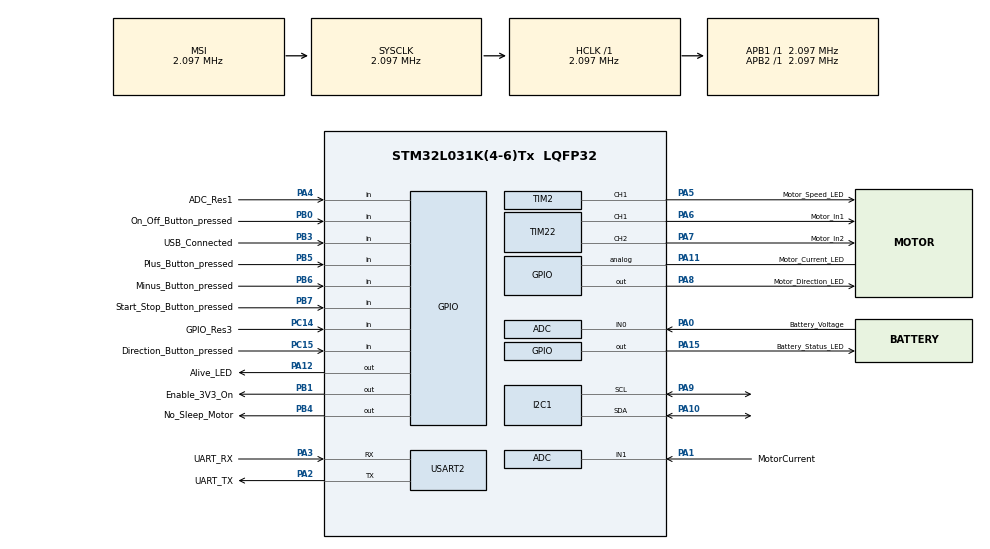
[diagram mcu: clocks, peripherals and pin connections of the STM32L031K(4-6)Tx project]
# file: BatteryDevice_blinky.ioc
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I2C1.Timing=0x00000608
Mcu.Family=STM32L0
Mcu.Name=STM32L031K(4-6)Tx
Mcu.Package=LQFP32
PA0-CK_IN.GPIO_Label=Battery_Voltage
PA0-CK_IN.Mode=IN0
PA0-CK_IN.Signal=ADC_IN0
PA1.GPIO_Label=MotorCurrent
PA1.Mode=IN1
PA1.Signal=ADC_IN1
PA10.Mode=I2C
PA10.Signal=I2C1_SDA
PA11.GPIO_Label=Motor_Current_LED
PA11.Signal=GPIO_Analog
PA12.GPIO_Label=Alive_LED
PA12.Signal=GPIO_Output
PA13.Mode=Serial_Wire
PA13.Signal=SYS_SWDIO
PA14.Mode=Serial_Wire
PA14.Signal=SYS_SWCLK
PA15.GPIO_Label=Battery_Status_LED
PA15.Signal=GPIO_Output
PA2.GPIO_Label=UART_TX
PA2.Mode=Asynchronous
PA2.Signal=USART2_TX
PA3.GPIO_Label=UART_RX
PA3.Mode=Asynchronous
PA3.Signal=USART2_RX
PA4.GPIO_Label=ADC_Res1
PA4.Signal=GPIO_Input
PA5.GPIO_Label=Motor_Speed_LED
PA5.Signal=S_TIM2_CH1
PA6.GPIO_Label=Motor_In1
PA6.Signal=S_TIM22_CH1
PA7.GPIO_Label=Motor_In2
PA7.Signal=S_TIM22_CH2
PA8.GPIO_Label=Motor_Direction_LED
PA8.Signal=GPIO_Output
PA9.Mode=I2C
PA9.Signal=I2C1_SCL
PB0.GPIO_Label=On_Off_Button_pressed
PB0.Signal=GPIO_Input
PB1.GPIO_Label=Enable_3V3_On
PB1.Signal=GPIO_Output
PB3.GPIO_Label=USB_Connected
PB3.Signal=GPIO_Input
PB4.GPIO_Label=No_Sleep_Motor
PB4.Signal=GPIO_Output
PB5.GPIO_Label=Plus_Button_pressed
PB5.Signal=GPIO_Input
PB6.GPIO_Label=Minus_Button_pressed
PB6.Signal=GPIO_Input
PB7.GPIO_Label=Start_Stop_Button_pressed
PB7.Signal=GPIO_Input
PC14-OSC32_IN.GPIO_Label=GPIO_Res3
PC14-OSC32_IN.Signal=GPIO_Input
PC15-OSC32_OUT.GPIO_Label=Direction_Button_pressed
PC15-OSC32_OUT.Signal=GPIO_Input
ProjectManager.HeapSize=0x200
ProjectManager.StackSize=0x400
ProjectManager.TargetToolchain=STM32CubeIDE
RCC.AHBFreq_Value=2097000
RCC.APB1Freq_Value=2097000
RCC.APB1TimFreq_Value=2097000
RCC.APB2Freq_Value=2097000
RCC.APB2TimFreq_Value=2097000
RCC.HSE_VALUE=8000000
RCC.HSI16_VALUE=16000000
RCC.HSI_VALUE=16000000
RCC.LSE_VALUE=32768
RCC.MSI_VALUE=2097000
RCC.SYSCLKFreq_VALUE=2097000
RCC.VCOOutputFreq_Value=48000000
SH.S_TIM22_CH1.0=TIM22_CH1,PWM Generation1 CH1
SH.S_TIM22_CH2.0=TIM22_CH2,PWM Generation2 CH2
SH.S_TIM2_CH1.0=TIM2_CH1,PWM Generation1 CH1
TIM2.Channel-PWM\ Generation1\ CH1=TIM_CHANNEL_1
TIM2.Period=100
TIM2.Prescaler=16000-1
TIM22.Channel-PWM\ Generation1\ CH1=TIM_CHANNEL_1
TIM22.Channel-PWM\ Generation2\ CH2=TIM_CHANNEL_2
USART2.VirtualMode-Asynchronous=VM_ASYNC
board=custom

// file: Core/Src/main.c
/* USER CODE BEGIN Header */
/**
  ******************************************************************************
  * @file           : main.c
  * @brief          : Main program body
  ******************************************************************************
  * @attention
  *
  * Copyright (c) 2025 STMicroelectronics.
  * All rights reserved.
  *
  * This software is licensed under terms that can be found in the LICENSE file
  * in the root directory of this software component.
  * If no LICENSE file comes with this software, it is provided AS-IS.
  *
  ******************************************************************************
  */
/* USER CODE END Header */
#include "main.h"

ADC_HandleTypeDef hadc;

I2C_HandleTypeDef hi2c1;

TIM_HandleTypeDef htim2;
TIM_HandleTypeDef htim22;

UART_HandleTypeDef huart2;

void SystemClock_Config(void);
static void MX_GPIO_Init(void);
static void MX_ADC_Init(void);
static void MX_I2C1_Init(void);
static void MX_TIM2_Init(void);
static void MX_TIM22_Init(void);
static void MX_USART2_UART_Init(void);

int main(void)
{

  /* MCU Configuration--------------------------------------------------------*/

  /* Reset of all peripherals, Initializes the Flash interface and the Systick. */
  HAL_Init();

  /* Configure the system clock */
  SystemClock_Config();

  /* Initialize all configured peripherals */
  MX_GPIO_Init();
  MX_ADC_Init();
  MX_I2C1_Init();
  MX_TIM2_Init();
  MX_TIM22_Init();
  MX_USART2_UART_Init();

  /* Infinite loop */
  /* USER CODE BEGIN WHILE */
  while (1)
  {
	  HAL_GPIO_TogglePin(Alive_LED_GPIO_Port, Alive_LED_Pin); // LED toggeln
	  HAL_DELAY(300);

	  /* USER CODE END WHILE */

  }
}

void SystemClock_Config(void)
{
  RCC_OscInitTypeDef RCC_OscInitStruct = {0};
  RCC_ClkInitTypeDef RCC_ClkInitStruct = {0};
  RCC_PeriphCLKInitTypeDef PeriphClkInit = {0};

  /** Configure the main internal regulator output voltage
  */
  __HAL_PWR_VOLTAGESCALING_CONFIG(PWR_REGULATOR_VOLTAGE_SCALE1);

  /** Initializes the RCC Oscillators according to the specified parameters
  * in the RCC_OscInitTypeDef structure.
  */
  RCC_OscInitStruct.OscillatorType = RCC_OSCILLATORTYPE_MSI;
  RCC_OscInitStruct.MSIState = RCC_MSI_ON;
  RCC_OscInitStruct.MSICalibrationValue = 0;
  RCC_OscInitStruct.MSIClockRange = RCC_MSIRANGE_5;
  RCC_OscInitStruct.PLL.PLLState = RCC_PLL_NONE;
  if (HAL_RCC_OscConfig(&RCC_OscInitStruct) != HAL_OK)
  {
    Error_Handler();
  }

  /** Initializes the CPU, AHB and APB buses clocks
  */
  RCC_ClkInitStruct.ClockType = RCC_CLOCKTYPE_HCLK|RCC_CLOCKTYPE_SYSCLK
                              |RCC_CLOCKTYPE_PCLK1|RCC_CLOCKTYPE_PCLK2;
  RCC_ClkInitStruct.SYSCLKSource = RCC_SYSCLKSOURCE_MSI;
  RCC_ClkInitStruct.AHBCLKDivider = RCC_SYSCLK_DIV1;
  RCC_ClkInitStruct.APB1CLKDivider = RCC_HCLK_DIV1;
  RCC_ClkInitStruct.APB2CLKDivider = RCC_HCLK_DIV1;

  if (HAL_RCC_ClockConfig(&RCC_ClkInitStruct, FLASH_LATENCY_0) != HAL_OK)
  {
    Error_Handler();
  }
  PeriphClkInit.PeriphClockSelection = RCC_PERIPHCLK_USART2|RCC_PERIPHCLK_I2C1;
  PeriphClkInit.Usart2ClockSelection = RCC_USART2CLKSOURCE_PCLK1;
  PeriphClkInit.I2c1ClockSelection = RCC_I2C1CLKSOURCE_PCLK1;
  if (HAL_RCCEx_PeriphCLKConfig(&PeriphClkInit) != HAL_OK)
  {
    Error_Handler();
  }
}

static void MX_ADC_Init(void)
{

  ADC_ChannelConfTypeDef sConfig = {0};

  /** Configure the global features of the ADC (Clock, Resolution, Data Alignment and number of conversion)
  */
  hadc.Instance = ADC1;
  hadc.Init.OversamplingMode = DISABLE;
  hadc.Init.ClockPrescaler = ADC_CLOCK_SYNC_PCLK_DIV1;
  hadc.Init.Resolution = ADC_RESOLUTION_12B;
  hadc.Init.SamplingTime = ADC_SAMPLETIME_1CYCLE_5;
  hadc.Init.ScanConvMode = ADC_SCAN_DIRECTION_FORWARD;
  hadc.Init.DataAlign = ADC_DATAALIGN_RIGHT;
  hadc.Init.ContinuousConvMode = DISABLE;
  hadc.Init.DiscontinuousConvMode = DISABLE;
  hadc.Init.ExternalTrigConvEdge = ADC_EXTERNALTRIGCONVEDGE_NONE;
  hadc.Init.ExternalTrigConv = ADC_SOFTWARE_START;
  hadc.Init.DMAContinuousRequests = DISABLE;
  hadc.Init.EOCSelection = ADC_EOC_SINGLE_CONV;
  hadc.Init.Overrun = ADC_OVR_DATA_PRESERVED;
  hadc.Init.LowPowerAutoWait = DISABLE;
  hadc.Init.LowPowerFrequencyMode = ENABLE;
  hadc.Init.LowPowerAutoPowerOff = DISABLE;
  if (HAL_ADC_Init(&hadc) != HAL_OK)
  {
    Error_Handler();
  }

  /** Configure for the selected ADC regular channel to be converted.
  */
  sConfig.Channel = ADC_CHANNEL_0;
  sConfig.Rank = ADC_RANK_CHANNEL_NUMBER;
  if (HAL_ADC_ConfigChannel(&hadc, &sConfig) != HAL_OK)
  {
    Error_Handler();
  }

  /** Configure for the selected ADC regular channel to be converted.
  */
  sConfig.Channel = ADC_CHANNEL_1;
  if (HAL_ADC_ConfigChannel(&hadc, &sConfig) != HAL_OK)
  {
    Error_Handler();
  }

}

static void MX_I2C1_Init(void)
{

  hi2c1.Instance = I2C1;
  hi2c1.Init.Timing = 0x00000608;
  hi2c1.Init.OwnAddress1 = 0;
  hi2c1.Init.AddressingMode = I2C_ADDRESSINGMODE_7BIT;
  hi2c1.Init.DualAddressMode = I2C_DUALADDRESS_DISABLE;
  hi2c1.Init.OwnAddress2 = 0;
  hi2c1.Init.OwnAddress2Masks = I2C_OA2_NOMASK;
  hi2c1.Init.GeneralCallMode = I2C_GENERALCALL_DISABLE;
  hi2c1.Init.NoStretchMode = I2C_NOSTRETCH_DISABLE;
  if (HAL_I2C_Init(&hi2c1) != HAL_OK)
  {
    Error_Handler();
  }

  /** Configure Analogue filter
  */
  if (HAL_I2CEx_ConfigAnalogFilter(&hi2c1, I2C_ANALOGFILTER_ENABLE) != HAL_OK)
  {
    Error_Handler();
  }

  /** Configure Digital filter
  */
  if (HAL_I2CEx_ConfigDigitalFilter(&hi2c1, 0) != HAL_OK)
  {
    Error_Handler();
  }

}

static void MX_TIM2_Init(void)
{

  TIM_MasterConfigTypeDef sMasterConfig = {0};
  TIM_OC_InitTypeDef sConfigOC = {0};

  htim2.Instance = TIM2;
  htim2.Init.Prescaler = 16000-1;
  htim2.Init.CounterMode = TIM_COUNTERMODE_UP;
  htim2.Init.Period = 100;
  htim2.Init.ClockDivision = TIM_CLOCKDIVISION_DIV1;
  htim2.Init.AutoReloadPreload = TIM_AUTORELOAD_PRELOAD_DISABLE;
  if (HAL_TIM_PWM_Init(&htim2) != HAL_OK)
  {
    Error_Handler();
  }
  sMasterConfig.MasterOutputTrigger = TIM_TRGO_RESET;
  sMasterConfig.MasterSlaveMode = TIM_MASTERSLAVEMODE_DISABLE;
  if (HAL_TIMEx_MasterConfigSynchronization(&htim2, &sMasterConfig) != HAL_OK)
  {
    Error_Handler();
  }
  sConfigOC.OCMode = TIM_OCMODE_PWM1;
  sConfigOC.Pulse = 0;
  sConfigOC.OCPolarity = TIM_OCPOLARITY_HIGH;
  sConfigOC.OCFastMode = TIM_OCFAST_DISABLE;
  if (HAL_TIM_PWM_ConfigChannel(&htim2, &sConfigOC, TIM_CHANNEL_1) != HAL_OK)
  {
    Error_Handler();
  }
  HAL_TIM_MspPostInit(&htim2);

}

static void MX_TIM22_Init(void)
{

  TIM_MasterConfigTypeDef sMasterConfig = {0};
  TIM_OC_InitTypeDef sConfigOC = {0};

  htim22.Instance = TIM22;
  htim22.Init.Prescaler = 0;
  htim22.Init.CounterMode = TIM_COUNTERMODE_UP;
  htim22.Init.Period = 65535;
  htim22.Init.ClockDivision = TIM_CLOCKDIVISION_DIV1;
  htim22.Init.AutoReloadPreload = TIM_AUTORELOAD_PRELOAD_DISABLE;
  if (HAL_TIM_PWM_Init(&htim22) != HAL_OK)
  {
    Error_Handler();
  }
  sMasterConfig.MasterOutputTrigger = TIM_TRGO_RESET;
  sMasterConfig.MasterSlaveMode = TIM_MASTERSLAVEMODE_DISABLE;
  if (HAL_TIMEx_MasterConfigSynchronization(&htim22, &sMasterConfig) != HAL_OK)
  {
    Error_Handler();
  }
  sConfigOC.OCMode = TIM_OCMODE_PWM1;
  sConfigOC.Pulse = 0;
  sConfigOC.OCPolarity = TIM_OCPOLARITY_HIGH;
  sConfigOC.OCFastMode = TIM_OCFAST_DISABLE;
  if (HAL_TIM_PWM_ConfigChannel(&htim22, &sConfigOC, TIM_CHANNEL_1) != HAL_OK)
  {
    Error_Handler();
  }
  if (HAL_TIM_PWM_ConfigChannel(&htim22, &sConfigOC, TIM_CHANNEL_2) != HAL_OK)
  {
    Error_Handler();
  }
  HAL_TIM_MspPostInit(&htim22);

}

static void MX_USART2_UART_Init(void)
{

  huart2.Instance = USART2;
  huart2.Init.BaudRate = 115200;
  huart2.Init.WordLength = UART_WORDLENGTH_8B;
  huart2.Init.StopBits = UART_STOPBITS_1;
  huart2.Init.Parity = UART_PARITY_NONE;
  huart2.Init.Mode = UART_MODE_TX_RX;
  huart2.Init.HwFlowCtl = UART_HWCONTROL_NONE;
  huart2.Init.OverSampling = UART_OVERSAMPLING_16;
  huart2.Init.OneBitSampling = UART_ONE_BIT_SAMPLE_DISABLE;
  huart2.AdvancedInit.AdvFeatureInit = UART_ADVFEATURE_NO_INIT;
  if (HAL_UART_Init(&huart2) != HAL_OK)
  {
    Error_Handler();
  }

}

static void MX_GPIO_Init(void)
{
  GPIO_InitTypeDef GPIO_InitStruct = {0};

  /* GPIO Ports Clock Enable */
  __HAL_RCC_GPIOC_CLK_ENABLE();
  __HAL_RCC_GPIOA_CLK_ENABLE();
  __HAL_RCC_GPIOB_CLK_ENABLE();

  /*Configure GPIO pin Output Level */
  HAL_GPIO_WritePin(GPIOB, Enable_3V3_On_Pin|No_Sleep_Motor_Pin, GPIO_PIN_RESET);

  /*Configure GPIO pin Output Level */
  HAL_GPIO_WritePin(GPIOA, Motor_Direction_LED_Pin|Alive_LED_Pin|Battery_Status_LED_Pin, GPIO_PIN_RESET);

  /*Configure GPIO pins : GPIO_Res3_Pin Direction_Button_pressed_Pin */
  GPIO_InitStruct.Pin = GPIO_Res3_Pin|Direction_Button_pressed_Pin;
  GPIO_InitStruct.Mode = GPIO_MODE_INPUT;
  GPIO_InitStruct.Pull = GPIO_NOPULL;
  HAL_GPIO_Init(GPIOC, &GPIO_InitStruct);

  /*Configure GPIO pin : ADC_Res1_Pin */
  GPIO_InitStruct.Pin = ADC_Res1_Pin;
  GPIO_InitStruct.Mode = GPIO_MODE_INPUT;
  GPIO_InitStruct.Pull = GPIO_NOPULL;
  HAL_GPIO_Init(ADC_Res1_GPIO_Port, &GPIO_InitStruct);

  /*Configure GPIO pins : On_Off_Button_pressed_Pin USB_Connected_Pin Plus_Button_pressed_Pin Minus_Button_pressed_Pin
                           Start_Stop_Button_pressed_Pin */
  GPIO_InitStruct.Pin = On_Off_Button_pressed_Pin|USB_Connected_Pin|Plus_Button_pressed_Pin|Minus_Button_pressed_Pin
                          |Start_Stop_Button_pressed_Pin;
  GPIO_InitStruct.Mode = GPIO_MODE_INPUT;
  GPIO_InitStruct.Pull = GPIO_NOPULL;
  HAL_GPIO_Init(GPIOB, &GPIO_InitStruct);

  /*Configure GPIO pins : Enable_3V3_On_Pin No_Sleep_Motor_Pin */
  GPIO_InitStruct.Pin = Enable_3V3_On_Pin|No_Sleep_Motor_Pin;
  GPIO_InitStruct.Mode = GPIO_MODE_OUTPUT_PP;
  GPIO_InitStruct.Pull = GPIO_NOPULL;
  GPIO_InitStruct.Speed = GPIO_SPEED_FREQ_LOW;
  HAL_GPIO_Init(GPIOB, &GPIO_InitStruct);

  /*Configure GPIO pins : Motor_Direction_LED_Pin Alive_LED_Pin Battery_Status_LED_Pin */
  GPIO_InitStruct.Pin = Motor_Direction_LED_Pin|Alive_LED_Pin|Battery_Status_LED_Pin;
  GPIO_InitStruct.Mode = GPIO_MODE_OUTPUT_PP;
  GPIO_InitStruct.Pull = GPIO_NOPULL;
  GPIO_InitStruct.Speed = GPIO_SPEED_FREQ_LOW;
  HAL_GPIO_Init(GPIOA, &GPIO_InitStruct);

  /*Configure GPIO pin : Motor_Current_LED_Pin */
  GPIO_InitStruct.Pin = Motor_Current_LED_Pin;
  GPIO_InitStruct.Mode = GPIO_MODE_ANALOG;
  GPIO_InitStruct.Pull = GPIO_NOPULL;
  HAL_GPIO_Init(Motor_Current_LED_GPIO_Port, &GPIO_InitStruct);

}

void Error_Handler(void)
{
  __disable_irq();
  while (1)
  {
  }
}
